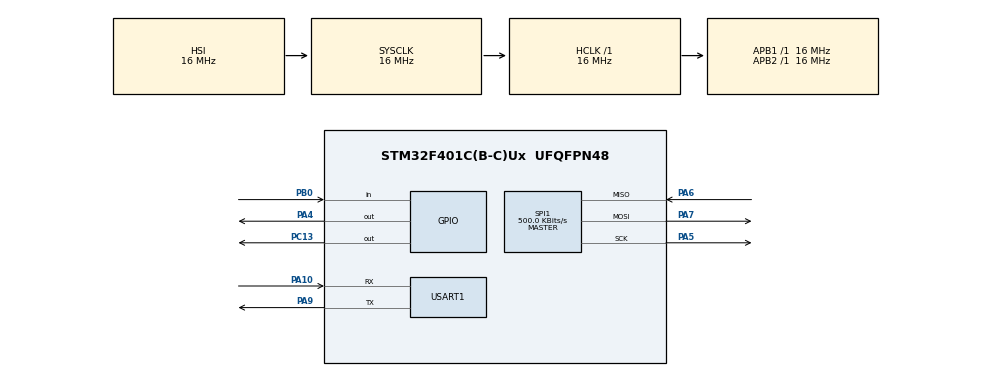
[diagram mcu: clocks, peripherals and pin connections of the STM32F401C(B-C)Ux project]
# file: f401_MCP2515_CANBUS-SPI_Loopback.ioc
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Mcu.Family=STM32F4
Mcu.Name=STM32F401C(B-C)Ux
Mcu.Package=UFQFPN48
NVIC.PriorityGroup=NVIC_PRIORITYGROUP_4
NVIC.USART1_IRQn=true\:0\:0\:false\:false\:true\:true\:true\:true
PA10.Mode=Asynchronous
PA10.Signal=USART1_RX
PA13.Mode=Serial_Wire
PA13.Signal=SYS_JTMS-SWDIO
PA14.Mode=Serial_Wire
PA14.Signal=SYS_JTCK-SWCLK
PA4.PinState=GPIO_PIN_SET
PA4.Signal=GPIO_Output
PA5.Mode=Full_Duplex_Master
PA5.Signal=SPI1_SCK
PA6.Mode=Full_Duplex_Master
PA6.Signal=SPI1_MISO
PA7.Mode=Full_Duplex_Master
PA7.Signal=SPI1_MOSI
PA9.Mode=Asynchronous
PA9.Signal=USART1_TX
PB0.GPIO_PuPd=GPIO_PULLUP
PB0.Signal=GPIO_Input
PC13-ANTI_TAMP.Signal=GPIO_Output
ProjectManager.HeapSize=0x200
ProjectManager.StackSize=0x400
ProjectManager.TargetToolchain=STM32CubeIDE
RCC.AHBFreq_Value=16000000
RCC.APB1Freq_Value=16000000
RCC.APB2Freq_Value=16000000
RCC.CortexFreq_Value=16000000
RCC.HSE_VALUE=25000000
RCC.HSI_VALUE=16000000
RCC.LSE_VALUE=32768
RCC.SYSCLKFreq_VALUE=16000000
RCC.VCOOutputFreq_Value=192000000
SPI1.BaudRatePrescaler=SPI_BAUDRATEPRESCALER_32
SPI1.CalculateBaudRate=500.0 KBits/s
SPI1.Direction=SPI_DIRECTION_2LINES
SPI1.Mode=SPI_MODE_MASTER
SPI1.VirtualType=VM_MASTER
USART1.VirtualMode=VM_ASYNC
board=custom

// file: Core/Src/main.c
/* USER CODE BEGIN Header */
/**
  ******************************************************************************
  * @file           : main.c
  * @brief          : Main program body
  ******************************************************************************
  * @attention
  *
  * Copyright (c) 2026 STMicroelectronics.
  * All rights reserved.
  *
  * This software is licensed under terms that can be found in the LICENSE file
  * in the root directory of this software component.
  * If no LICENSE file comes with this software, it is provided AS-IS.
  *
  ******************************************************************************
  */
/* USER CODE END Header */
#include "main.h"
#include "spi.h"
#include "usart.h"
#include "gpio.h"

/* USER CODE BEGIN Includes */
#include <stdio.h>
#include <string.h>
#include "mcp2515.h"
/* USER CODE END Includes */

void SystemClock_Config(void);

int main(void)
{

  /* MCU Configuration--------------------------------------------------------*/

  /* Reset of all peripherals, Initializes the Flash interface and the Systick. */
  HAL_Init();

  /* Configure the system clock */
  SystemClock_Config();

  /* Initialize all configured peripherals */
  MX_GPIO_Init();
  MX_USART1_UART_Init();
  MX_SPI1_Init();

  /* Infinite loop */
  /* USER CODE
   * BEGIN WHILE */
  while (1)
  {
	  /* Successful -> Output = CANCTRL = 0X87
	  //Mode Reading Test
	  uint8_t mode;
	  char buf[20];
	  uint8_t len;
	  mode = MCP2515_Read(MCP_CANCTRL);
	  len = (uint8_t)snprintf(buf, sizeof(buf), "CANCTRL=0x%02X\r\n", mode);
	  HAL_UART_Transmit(&huart1, (uint8_t*)buf, len, HAL_MAX_DELAY);
	  HAL_Delay(1000);
	  */
	  /*Successful  -> Output = CANCTRL =0X80
	  //Write Test
	  MCP2515_Reset();

	  MCP2515_Write(MCP_CANCTRL,0x80);

	  uint8_t value = MCP2515_Read(MCP_CANCTRL);
	  char buf[20];
	  uint8_t len = (uint8_t)snprintf(buf, sizeof(buf), "CANCTRL=0x%02X\r\n", value);
	  HAL_UART_Transmit(&huart1, (uint8_t*)buf, len, HAL_MAX_DELAY);
	  HAL_Delay(2000);
	   */
	  /* Successful -> Output  = Status = 0x00
	   //Status Test
	   uint8_t status;

	   status = MCP2515_ReadStatus();

	   char buf[20];
	   uint8_t len = (uint8_t)snprintf(buf, sizeof(buf), "Status=0x%02X\r\n", status);
	   HAL_UART_Transmit(&huart1, (uint8_t*)buf, len, HAL_MAX_DELAY);
	   HAL_Delay(2000);
	  	  */
	  /*
	   //Configuration Mode Test
	  uint8_t status = MCP2515_Read(MCP_CANSTAT);

	  char buf[30];
	  uint8_t len;
	  len = (uint8_t)snprintf(buf, sizeof(buf), "Status=0x%02X\r\n",status);
	  HAL_UART_Transmit(&huart1, (uint8_t*)buf, len, HAL_MAX_DELAY);

	  if(MCP2515_SetConfigurationMode())
	  {
	      len = (uint8_t)snprintf(buf, sizeof(buf), "Config Mode OK\r\n");
	  }
	  else
	  {
	      len = (uint8_t)snprintf(buf, sizeof(buf), "Config Mode FAIL\r\n");
	  }
	  HAL_UART_Transmit(&huart1, (uint8_t*)buf, len, HAL_MAX_DELAY);
	  HAL_Delay(2000);
	  */
	  /* Successful -> Output = Bitrate OK CNF1=0x00 CNF2=0x90 CNF3=0x02
	  //Set Bitrate Test
	  char buf[30];
	  uint8_t len;
	  if(MCP2515_SetBitrate(MCP2515_BITRATE_500KBPS))
	  {
	      len = (uint8_t)snprintf(buf, sizeof(buf), "Bitrate OK\r\n");
	  }
	  else
	  {
	      len = (uint8_t)snprintf(buf, sizeof(buf), "Bitrate FAILED\r\n");
	  }
	  HAL_UART_Transmit(&huart1, (uint8_t*)buf, len, HAL_MAX_DELAY);
	  HAL_Delay(1000);
	  len = (uint8_t)snprintf(buf, sizeof(buf), "CNF1=0x%02X\r\n", MCP2515_Read(MCP_CNF1));
	  HAL_UART_Transmit(&huart1, (uint8_t*)buf, len, HAL_MAX_DELAY);
	  HAL_Delay(1000);
	  len = (uint8_t)snprintf(buf, sizeof(buf), "CNF2=0x%02X\r\n", MCP2515_Read(MCP_CNF2));
	  HAL_UART_Transmit(&huart1, (uint8_t*)buf, len, HAL_MAX_DELAY);
	  HAL_Delay(1000);
	  len = (uint8_t)snprintf(buf, sizeof(buf), "CNF3=0x%02X\r\n", MCP2515_Read(MCP_CNF3));
	  HAL_UART_Transmit(&huart1, (uint8_t*)buf, len, HAL_MAX_DELAY);
	  HAL_Delay(1000);
	  */

	  /*
	   //Successful -> Output = 24 60 08
		// Tx Buffer Test
	  	  uint8_t txData[8] =
	  	  {
	  			  1,2,3,4,5,6,7,8
	  	  };

	  	  MCP2515_LoadTXBuffer(
	  			  0x123,
				  8,
				  txData
	  	  );

	  	  char buf[30];
	  	  uint8_t len;

	  	  len = (uint8_t)snprintf(buf, sizeof(buf), "%02X\r\n", MCP2515_Read(MCP_TXB0SIDH));
	  	  HAL_UART_Transmit(&huart1, (uint8_t*)buf, len, HAL_MAX_DELAY);
	  	  HAL_Delay(1000);
	  	  len= (uint8_t)snprintf(buf, sizeof(buf),"%02X\r\n",MCP2515_Read(MCP_TXB0SIDL));
	  	  HAL_UART_Transmit(&huart1, (uint8_t*)buf, len, HAL_MAX_DELAY);
	  	  HAL_Delay(1000);
	  	  len = (uint8_t)snprintf(buf, sizeof(buf), "%02X\r\n", MCP2515_Read(MCP_TXB0DLC));
	  	  HAL_UART_Transmit(&huart1, (uint8_t*)buf, len, HAL_MAX_DELAY);
	  	  HAL_Delay(1000);
	  	  */
		 // RST Test
	  MCP2515_Reset();
	  MCP2515_SetConfigurationMode();
	  MCP2515_SetBitrate(MCP2515_BITRATE_500KBPS);
	  MCP2515_SetLoopbackMode();

	  uint8_t txData[8] = {1, 2, 3, 4, 5, 6, 7, 8};
	  MCP2515_LoadTXBuffer(0x123, 8, txData);
	  MCP2515_RequestToSend();

	  HAL_Delay(10);  //Wait to  MCP2515 frame processing

	  MCP2515_Frame_t rxFrame;
	  if(MCP2515_ReadRXBuffer(&rxFrame))
	  {
	      char buf[30];
	      uint8_t len;

	      len = (uint8_t)snprintf(buf, sizeof(buf), "ID=0x%03X\r\n", rxFrame.id);
	      HAL_UART_Transmit(&huart1, (uint8_t*)buf, len, HAL_MAX_DELAY);
	      HAL_Delay(1000);
	      len = (uint8_t)snprintf(buf, sizeof(buf), "DLC=%d\r\n", rxFrame.dlc);
	      HAL_UART_Transmit(&huart1, (uint8_t*)buf, len, HAL_MAX_DELAY);
	      HAL_Delay(1000);
	      for(uint8_t i = 0; i < rxFrame.dlc; i++)
	      {
	          len = (uint8_t)snprintf(buf, sizeof(buf), "D%d=%d\r\n", i, rxFrame.data[i]);
	          HAL_UART_Transmit(&huart1, (uint8_t*)buf, len, HAL_MAX_DELAY);
	          HAL_Delay(1000);
	      }
	  }
	  else
	  {
	      char buf[30];
	      uint8_t len = (uint8_t)snprintf(buf, sizeof(buf), "RX FAILED\r\n");
	      HAL_UART_Transmit(&huart1, (uint8_t*)buf, len, HAL_MAX_DELAY);
	  }

    /* USER CODE END WHILE */

  }
}

void SystemClock_Config(void)
{
  RCC_OscInitTypeDef RCC_OscInitStruct = {0};
  RCC_ClkInitTypeDef RCC_ClkInitStruct = {0};

  /** Configure the main internal regulator output voltage
  */
  __HAL_RCC_PWR_CLK_ENABLE();
  __HAL_PWR_VOLTAGESCALING_CONFIG(PWR_REGULATOR_VOLTAGE_SCALE2);

  /** Initializes the RCC Oscillators according to the specified parameters
  * in the RCC_OscInitTypeDef structure.
  */
  RCC_OscInitStruct.OscillatorType = RCC_OSCILLATORTYPE_HSI;
  RCC_OscInitStruct.HSIState = RCC_HSI_ON;
  RCC_OscInitStruct.HSICalibrationValue = RCC_HSICALIBRATION_DEFAULT;
  RCC_OscInitStruct.PLL.PLLState = RCC_PLL_NONE;
  if (HAL_RCC_OscConfig(&RCC_OscInitStruct) != HAL_OK)
  {
    Error_Handler();
  }

  /** Initializes the CPU, AHB and APB buses clocks
  */
  RCC_ClkInitStruct.ClockType = RCC_CLOCKTYPE_HCLK|RCC_CLOCKTYPE_SYSCLK
                              |RCC_CLOCKTYPE_PCLK1|RCC_CLOCKTYPE_PCLK2;
  RCC_ClkInitStruct.SYSCLKSource = RCC_SYSCLKSOURCE_HSI;
  RCC_ClkInitStruct.AHBCLKDivider = RCC_SYSCLK_DIV1;
  RCC_ClkInitStruct.APB1CLKDivider = RCC_HCLK_DIV1;
  RCC_ClkInitStruct.APB2CLKDivider = RCC_HCLK_DIV1;

  if (HAL_RCC_ClockConfig(&RCC_ClkInitStruct, FLASH_LATENCY_0) != HAL_OK)
  {
    Error_Handler();
  }
}

void Error_Handler(void)
{
  __disable_irq();
  while (1)
  {
  }
}
